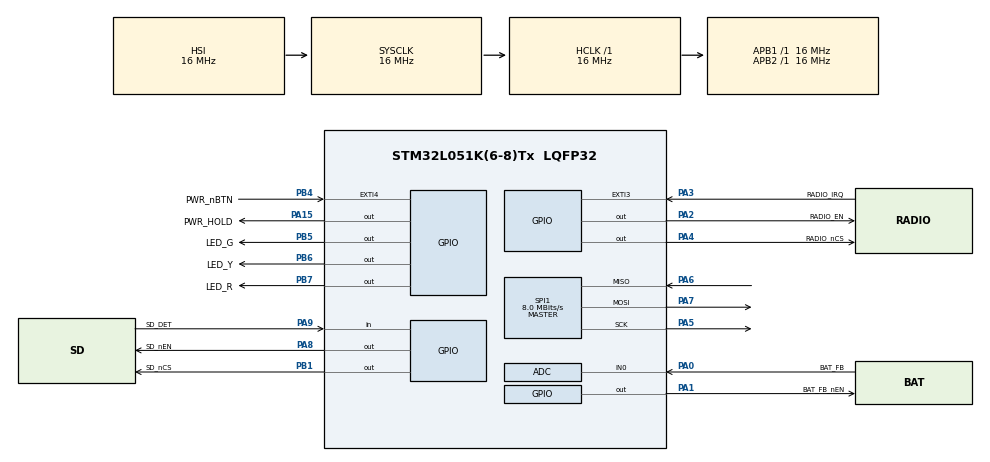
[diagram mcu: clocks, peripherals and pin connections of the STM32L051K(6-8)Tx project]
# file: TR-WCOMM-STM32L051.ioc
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ADC.SamplingTime=ADC_SAMPLETIME_160CYCLES_5
Dma.ADC.0.Direction=DMA_PERIPH_TO_MEMORY
Dma.ADC.0.Instance=DMA1_Channel1
Dma.ADC.0.MemDataAlignment=DMA_MDATAALIGN_HALFWORD
Dma.ADC.0.MemInc=DMA_MINC_ENABLE
Dma.ADC.0.Mode=DMA_NORMAL
Dma.ADC.0.PeriphDataAlignment=DMA_PDATAALIGN_HALFWORD
Dma.ADC.0.PeriphInc=DMA_PINC_DISABLE
Dma.ADC.0.Priority=DMA_PRIORITY_LOW
Dma.Request0=ADC
Dma.Request1=SPI1_RX
Dma.Request2=SPI1_TX
Dma.SPI1_RX.1.Direction=DMA_PERIPH_TO_MEMORY
Dma.SPI1_RX.1.Instance=DMA1_Channel2
Dma.SPI1_RX.1.MemDataAlignment=DMA_MDATAALIGN_BYTE
Dma.SPI1_RX.1.MemInc=DMA_MINC_ENABLE
Dma.SPI1_RX.1.Mode=DMA_NORMAL
Dma.SPI1_RX.1.PeriphDataAlignment=DMA_PDATAALIGN_BYTE
Dma.SPI1_RX.1.PeriphInc=DMA_PINC_DISABLE
Dma.SPI1_RX.1.Priority=DMA_PRIORITY_LOW
Dma.SPI1_TX.2.Direction=DMA_MEMORY_TO_PERIPH
Dma.SPI1_TX.2.Instance=DMA1_Channel3
Dma.SPI1_TX.2.MemDataAlignment=DMA_MDATAALIGN_BYTE
Dma.SPI1_TX.2.MemInc=DMA_MINC_ENABLE
Dma.SPI1_TX.2.Mode=DMA_NORMAL
Dma.SPI1_TX.2.PeriphDataAlignment=DMA_PDATAALIGN_BYTE
Dma.SPI1_TX.2.PeriphInc=DMA_PINC_DISABLE
Dma.SPI1_TX.2.Priority=DMA_PRIORITY_LOW
FATFS._FS_NORTC=1
FATFS._MAX_SS=1024
FATFS._NORTC_MDAY=10
FATFS._NORTC_MON=4
FATFS._NORTC_YEAR=2022
FATFS._USE_LFN=1
LPTIM1.ClockPrescaler=LPTIM_PRESCALER_DIV32
Mcu.Family=STM32L0
Mcu.Name=STM32L051K(6-8)Tx
Mcu.Package=LQFP32
NVIC.ADC1_COMP_IRQn=true\:0\:0\:false\:false\:true\:true\:true\:true
NVIC.DMA1_Channel1_IRQn=true\:0\:0\:false\:false\:true\:false\:true\:true
NVIC.DMA1_Channel2_3_IRQn=true\:0\:0\:false\:false\:true\:false\:true\:true
NVIC.EXTI2_3_IRQn=true\:0\:0\:false\:false\:true\:true\:true\:true
NVIC.EXTI4_15_IRQn=true\:0\:0\:false\:false\:true\:true\:true\:true
NVIC.LPTIM1_IRQn=true\:0\:0\:false\:false\:true\:true\:true\:true
NVIC.SPI1_IRQn=true\:0\:0\:false\:false\:true\:true\:true\:true
PA0.GPIO_Label=BAT_FB
PA0.Mode=IN0
PA0.Signal=ADC_IN0
PA1.GPIO_Label=BAT_FB_nEN
PA1.GPIO_ModeDefaultOutputPP=GPIO_MODE_OUTPUT_OD
PA1.GPIO_PuPd=GPIO_NOPULL
PA1.Signal=GPIO_Output
PA13.GPIO_Label=SWDIO
PA13.Mode=Serial_Wire
PA13.Signal=SYS_SWDIO
PA14.GPIO_Label=SWCLK
PA14.Mode=Serial_Wire
PA14.Signal=SYS_SWCLK
PA15.GPIO_Label=PWR_HOLD
PA15.GPIO_ModeDefaultOutputPP=GPIO_MODE_OUTPUT_OD
PA15.GPIO_PuPd=GPIO_NOPULL
PA15.Signal=GPIO_Output
PA2.GPIO_Label=RADIO_EN
PA2.GPIO_Speed=GPIO_SPEED_FREQ_VERY_HIGH
PA2.Signal=GPIO_Output
PA3.GPIO_Label=RADIO_IRQ
PA3.GPIO_ModeDefaultEXTI=GPIO_MODE_IT_FALLING
PA3.Signal=GPXTI3
PA4.GPIO_Label=RADIO_nCS
PA4.GPIO_Speed=GPIO_SPEED_FREQ_VERY_HIGH
PA4.PinState=GPIO_PIN_SET
PA4.Signal=GPIO_Output
PA5.Mode=Full_Duplex_Master
PA5.Signal=SPI1_SCK
PA6.Mode=Full_Duplex_Master
PA6.Signal=SPI1_MISO
PA7.Mode=Full_Duplex_Master
PA7.Signal=SPI1_MOSI
PA8.GPIO_Label=SD_nEN
PA8.GPIO_ModeDefaultOutputPP=GPIO_MODE_OUTPUT_OD
PA8.GPIO_PuPd=GPIO_NOPULL
PA8.GPIO_Speed=GPIO_SPEED_FREQ_LOW
PA8.PinState=GPIO_PIN_SET
PA8.Signal=GPIO_Output
PA9.GPIO_Label=SD_DET
PA9.Signal=GPIO_Input
PB1.GPIO_Label=SD_nCS
PB1.GPIO_Speed=GPIO_SPEED_FREQ_VERY_HIGH
PB1.Signal=GPIO_Output
PB4.GPIO_Label=PWR_nBTN
PB4.Signal=GPXTI4
PB5.GPIO_Label=LED_G
PB5.Signal=GPIO_Output
PB6.GPIO_Label=LED_Y
PB6.Signal=GPIO_Output
PB7.GPIO_Label=LED_R
PB7.Signal=GPIO_Output
ProjectManager.HeapSize=0x200
ProjectManager.StackSize=0x400
ProjectManager.TargetToolchain=STM32CubeIDE
RCC.AHBFreq_Value=16000000
RCC.APB1Freq_Value=16000000
RCC.APB1TimFreq_Value=16000000
RCC.APB2Freq_Value=16000000
RCC.APB2TimFreq_Value=16000000
RCC.HCLKFreq_Value=16000000
RCC.HSI16_VALUE=16000000
RCC.HSI_VALUE=16000000
RCC.LSE_VALUE=32768
RCC.MSI_VALUE=2097000
RCC.SYSCLKFreq_VALUE=16000000
RCC.SYSCLKSource=RCC_SYSCLKSOURCE_HSI
RCC.VCOOutputFreq_Value=48000000
SPI1.CalculateBaudRate=8.0 MBits/s
SPI1.Direction=SPI_DIRECTION_2LINES
SPI1.Mode=SPI_MODE_MASTER
SPI1.VirtualType=VM_MASTER
VP_ADC_Vref_Input.Mode=IN-Vrefint
VP_FATFS_VS_Generic.Mode=User_defined
VP_LPTIM1_VS_LPTIM_counterModeInternalClock.Mode=Counts__internal_clock_event_00
board=custom

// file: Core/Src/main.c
/* USER CODE BEGIN Header */
/**
  ******************************************************************************
  * @file           : main.c
  * @brief          : Main program body
  ******************************************************************************
  * @attention
  *
  * Copyright (c) 2022 STMicroelectronics.
  * All rights reserved.
  *
  * This software is licensed under terms that can be found in the LICENSE file
  * in the root directory of this software component.
  * If no LICENSE file comes with this software, it is provided AS-IS.
  *
  ******************************************************************************
  */
/* USER CODE END Header */
#include "main.h"
#include "adc.h"
#include "dma.h"
#include "fatfs.h"
#include "lptim.h"
#include "spi.h"
#include "gpio.h"

/* USER CODE BEGIN Includes */
#include <App/CppMainCaller.h>
/* USER CODE END Includes */

void SystemClock_Config(void);

int main(void)
{

  /* MCU Configuration--------------------------------------------------------*/

  /* Reset of all peripherals, Initializes the Flash interface and the Systick. */
  HAL_Init();

  /* Configure the system clock */
  SystemClock_Config();

  /* Initialize all configured peripherals */
  MX_GPIO_Init();
  MX_DMA_Init();
  MX_ADC_Init();
  MX_LPTIM1_Init();
  MX_SPI1_Init();
  MX_FATFS_Init();
  /* USER CODE BEGIN 2 */
  CppMainCaller();
  /* USER CODE END 2 */

  /* Infinite loop */
  while (1)
  {

  }
}

void SystemClock_Config(void)
{
  RCC_OscInitTypeDef RCC_OscInitStruct = {0};
  RCC_ClkInitTypeDef RCC_ClkInitStruct = {0};
  RCC_PeriphCLKInitTypeDef PeriphClkInit = {0};

  /** Configure the main internal regulator output voltage
  */
  __HAL_PWR_VOLTAGESCALING_CONFIG(PWR_REGULATOR_VOLTAGE_SCALE1);

  /** Initializes the RCC Oscillators according to the specified parameters
  * in the RCC_OscInitTypeDef structure.
  */
  RCC_OscInitStruct.OscillatorType = RCC_OSCILLATORTYPE_HSI;
  RCC_OscInitStruct.HSIState = RCC_HSI_ON;
  RCC_OscInitStruct.HSICalibrationValue = RCC_HSICALIBRATION_DEFAULT;
  RCC_OscInitStruct.PLL.PLLState = RCC_PLL_NONE;
  if (HAL_RCC_OscConfig(&RCC_OscInitStruct) != HAL_OK)
  {
    Error_Handler();
  }

  /** Initializes the CPU, AHB and APB buses clocks
  */
  RCC_ClkInitStruct.ClockType = RCC_CLOCKTYPE_HCLK|RCC_CLOCKTYPE_SYSCLK
                              |RCC_CLOCKTYPE_PCLK1|RCC_CLOCKTYPE_PCLK2;
  RCC_ClkInitStruct.SYSCLKSource = RCC_SYSCLKSOURCE_HSI;
  RCC_ClkInitStruct.AHBCLKDivider = RCC_SYSCLK_DIV1;
  RCC_ClkInitStruct.APB1CLKDivider = RCC_HCLK_DIV1;
  RCC_ClkInitStruct.APB2CLKDivider = RCC_HCLK_DIV1;

  if (HAL_RCC_ClockConfig(&RCC_ClkInitStruct, FLASH_LATENCY_0) != HAL_OK)
  {
    Error_Handler();
  }
  PeriphClkInit.PeriphClockSelection = RCC_PERIPHCLK_LPTIM1;
  PeriphClkInit.LptimClockSelection = RCC_LPTIM1CLKSOURCE_PCLK;

  if (HAL_RCCEx_PeriphCLKConfig(&PeriphClkInit) != HAL_OK)
  {
    Error_Handler();
  }
}

void Error_Handler(void)
{
  __disable_irq();
  while (1)
  {
  }
}
